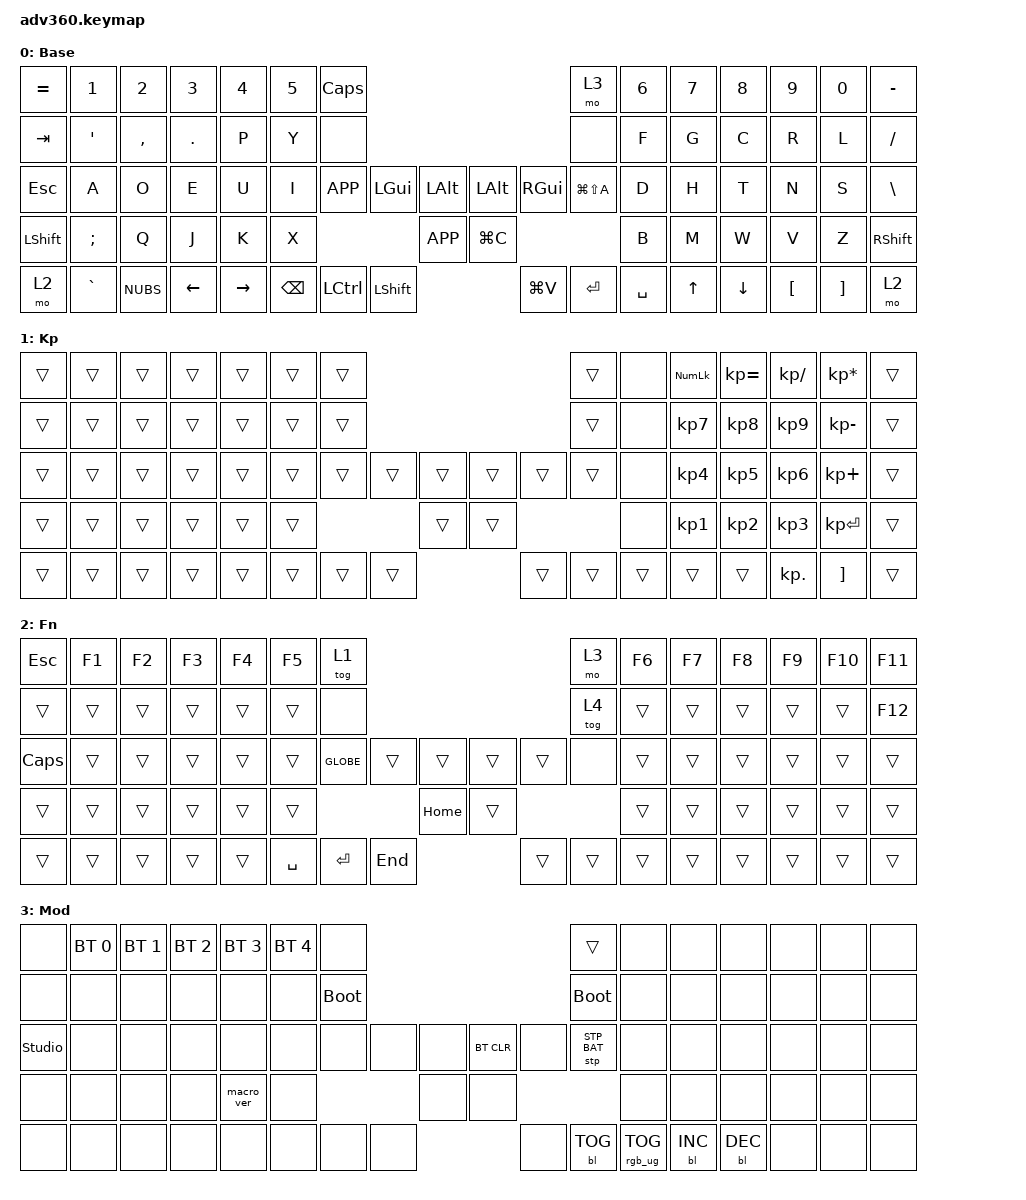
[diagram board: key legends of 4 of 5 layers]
#include <behaviors.dtsi>
#include <dt-bindings/zmk/keys.h>
#include <dt-bindings/zmk/bt.h>
#include <dt-bindings/zmk/rgb.h>
#include <dt-bindings/zmk/stp.h>
#include <dt-bindings/zmk/backlight.h>
#include <dt-bindings/zmk/pointing.h>

/ {
    behaviors {
      #include "macros.dtsi"
      #include "version.dtsi"
      #ifndef VERSION_MACRO
      macro_ver: macro_ver {
        compatible = "zmk,behavior-macro";
        label = "macro_version";
        #binding-cells = <0>;
        bindings = <&kp RET>;
      };
      #endif

      hm: homerow_mods {
          compatible = "zmk,behavior-hold-tap";
          label = "HOMEROW_MODS";
          #binding-cells = <2>;
          tapping-term-ms = <200>;
          quick_tap_ms = <175>;
          flavor = "tap-preferred";
          bindings = <&kp>, <&kp>;
      };
    };

  keymap {
    compatible = "zmk,keymap";

    default_layer {
      display-name = "Base";
      bindings = <
        &kp EQUAL &kp N1    &kp N2    &kp N3   &kp N4     &kp N5 &kp CAPS                                                            &mo 3         &kp N6 &kp N7 &kp N8   &kp N9   &kp N0   &kp MINUS
        &kp TAB   &kp SQT   &kp COMMA &kp DOT  &kp P      &kp Y  &none                                                               &none         &kp F  &kp G  &kp C    &kp R    &kp L    &kp FSLH
        &kp ESC   &kp A     &kp O     &kp E    &kp U      &kp I  &kp K_APP       &kp LGUI  &kp LALT    &kp LALT  &kp RGUI            &kp LG(LS(A)) &kp D  &kp H  &kp T    &kp N    &kp S    &kp BSLH
        &kp LSHFT &kp SEMI  &kp Q     &kp J    &kp K      &kp X                            &kp K_APP   &kp LG(C)                                   &kp B  &kp M  &kp W    &kp V    &kp Z    &kp RSHFT
        &mo 2     &kp GRAVE &kp NUBS  &kp LEFT &kp RIGHT                &kp BSPC &kp LCTRL &kp LSHIFT  &kp LG(V) &kp ENTER &kp SPACE                      &kp UP &kp DOWN &kp LBKT &kp RBKT &mo 2
      >;
    };
    keypad {
      display-name = "Kp";
      bindings = <
        &trans &trans &trans &trans &trans &trans &trans                                          &trans &none  &kp KP_NUM &kp KP_EQUAL &kp KP_DIVIDE &kp KP_MULTIPLY &trans
        &trans &trans &trans &trans &trans &trans &trans                                          &trans &none  &kp KP_N7  &kp KP_N8    &kp KP_N9     &kp KP_MINUS    &trans
        &trans &trans &trans &trans &trans &trans &trans       &trans &trans &trans &trans        &trans &none  &kp KP_N4  &kp KP_N5    &kp KP_N6     &kp KP_PLUS     &trans
        &trans &trans &trans &trans &trans &trans                     &trans &trans                      &none  &kp KP_N1  &kp KP_N2    &kp KP_N3     &kp KP_ENTER    &trans
        &trans &trans &trans &trans &trans              &trans &trans &trans &trans &trans &trans               &trans     &trans       &kp KP_DOT    &kp RBKT        &trans
      >;
    };
    fn {
      display-name = "Fn";
      bindings = <
        &kp ESC  &kp F1 &kp F2 &kp F3 &kp F4 &kp F5 &tog 1                                                 &mo 3  &kp F6 &kp F7 &kp F8 &kp F9 &kp F10 &kp F11
        &trans   &trans &trans &trans &trans &trans &none                                                  &tog 4 &trans &trans &trans &trans  &trans &kp F12
        &kp CAPS &trans &trans &trans &trans &trans &kp GLOBE           &trans &trans   &trans &trans      &none  &trans &trans &trans &trans  &trans &trans
        &trans   &trans &trans &trans &trans &trans                            &kp HOME &trans                    &trans &trans &trans &trans  &trans &trans
        &trans   &trans &trans &trans &trans               &kp SPACE &kp ENTER &kp END  &trans &trans &trans             &trans &trans &trans  &trans &trans
      >;
    };
    mod {
      display-name = "Mod";
      bindings = <
        &none          &bt BT_SEL 0 &bt BT_SEL 1 &bt BT_SEL 2 &bt BT_SEL 3 &bt BT_SEL 4 &none                                                              &trans       &none  &none        &none        &none &none &none
        &none          &none        &none        &none        &none        &none        &bootloader                                                        &bootloader  &none  &none        &none        &none &none &none
        &studio_unlock &none        &none        &none        &none        &none        &none             &none &none &bt BT_CLR  &none                    &stp STP_BAT &none  &none        &none        &none &none &none
        &none          &none        &none        &none        &macro_ver   &none                                &none &none                                             &none  &none        &none        &none &none &none
        &none          &none        &none        &none        &none                                &none &none  &none &none &bl BL_TOG  &rgb_ug  RGB_TOG                       &bl BL_INC   &bl BL_DEC   &none &none &none
      >;
    };

    querty {
      display-name = "querty";
      bindings = <
        &kp EQUAL &kp N1  &kp N2  &kp N3  &kp N4  &kp N5 &trans                                                  &trans  &kp N6  &kp N7  &kp N8    &kp N9   &kp N0   &kp MINUS
        &kp TAB   &kp Q   &kp W   &kp E   &kp R   &kp T  &trans                                                  &tog 4  &kp Y   &kp U   &kp I     &kp O    &kp P    &kp BSLH
        &kp ESC   &kp A   &kp S   &kp D   &kp F   &kp G  &trans               &trans &trans &trans &trans        &trans  &kp H   &kp J   &kp K     &kp L    &kp SEMI &kp SQT
        &kp LSHFT &kp Z   &kp X   &kp C   &kp V   &kp B                              &trans &trans                       &kp N   &kp M   &kp COMMA &kp DOT  &kp FSLH &kp RSHFT
        &mo 2     &trans  &trans  &trans  &trans  &trans               &trans &trans &trans &trans &trans &trans         &trans  &trans  &trans    &trans   &trans   &mo 2
      >;
    };

    extra1 { 
      display-name = "Red";    
      status = "reserved";
    };

    extra2 { 
      display-name = "Purple";    
      status = "reserved";
    };

    extra3 { 
      display-name = "Cyan";    
      status = "reserved";
    };

    extra4 { 
      display-name = "Yellow";    
      status = "reserved";
    };

  };
};
